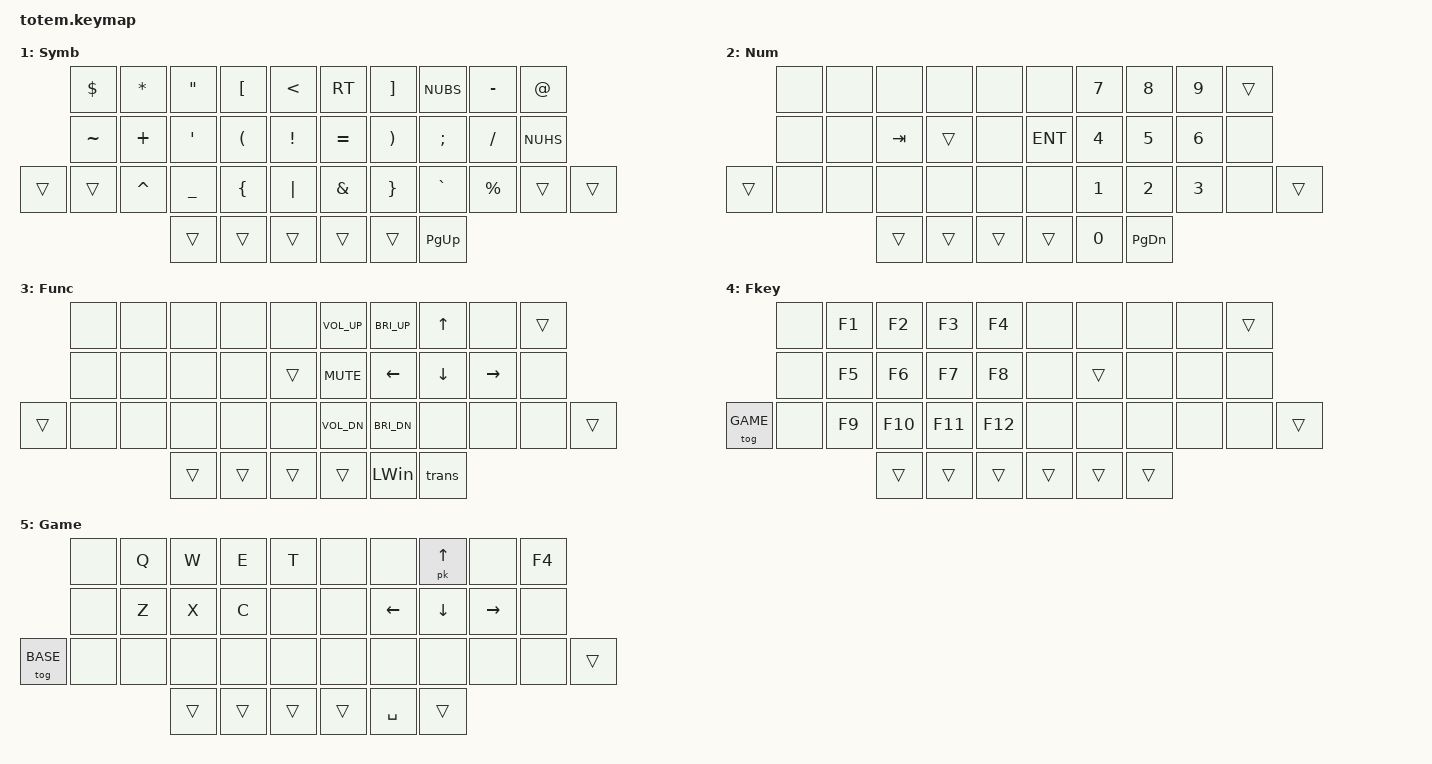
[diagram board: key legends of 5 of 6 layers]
//
//                                                        ▀▀▀▀▀     ▀▀▀▀▀          ▀▀█▀▀
//                                                        ▄▀▀▀▄  ▄  ▄▀▀▀▄  ▄  ▄▀▀▀▄  █  ▄▀▀▀▄
//                                                        █   █  █  █   █  █  █   █  █  █   █
//                                                         ▀▀▀   █   ▀▀▀   █   ▀▀▀   ▀   ▀▀▀
//                                                               █      ▄▄▄█▄▄▄    █   █  
//                                                               ▀      █  █  █     █▄█
//                                                             ▀▀▀▀▀    █  █  █      ▀
//                                                                      ▀  ▀  ▀
//
// ▄▄▄▄▄▄▄▄▄▄▄▄▄▄▄▄▄▄▄▄▄▄▄▄▄▄▄▄▄▄▄▄▄▄▄▄▄▄▄▄▄▄▄▄▄▄▄▄▄▄▄▄▄▄▄▄▄▄▄▄▄▄▄▄▄▄▄▄▄▄▄▄▄▄▄▄▄▄▄▄▄▄▄▄▄▄▄▄▄▄▄▄▄▄▄▄▄▄▄▄▄▄▄▄▄▄▄▄▄▄▄▄▄▄▄▄▄▄▄▄▄▄▄▄▄▄▄▄▄▄▄▄▄▄▄▄▄▄▄▄▄▄▄▄▄▄▄▄▄
       

#include <behaviors.dtsi>
#include <dt-bindings/zmk/keys.h>
#include <dt-bindings/zmk/bt.h>
#include <dt-bindings/zmk/outputs.h>

#define BASE 0
#define SYMB 1
#define NUM  2
#define FUNC 3
#define FKEY 4
#define GAME 5

&mt {
  flavor = "tap-preferred";
};

/ {
    combos {
            compatible = "zmk,combos";
            combo_esc {
                timeout-ms = <50>;
                key-positions = <0 1>;
                bindings = <&kp ESC>;
            };
                                                                                                           
    };

        keymap {
                compatible = "zmk,keymap";
// ▄▄▄▄▄▄▄▄▄▄▄▄▄▄▄▄▄▄▄▄▄▄▄▄▄▄▄▄▄▄▄▄▄▄▄▄▄▄▄▄▄▄▄▄▄▄▄▄▄▄▄▄▄▄▄▄▄▄▄▄▄▄▄▄▄▄▄▄▄▄▄▄▄▄▄▄▄▄▄▄▄▄▄▄▄▄▄▄▄▄▄▄▄▄▄▄▄▄▄▄▄▄▄▄▄▄▄▄▄▄▄▄▄▄▄▄▄▄▄▄▄▄▄▄▄▄▄▄▄▄▄▄▄▄▄▄▄▄▄▄▄▄▄▄▄▄▄▄▄

                base_layer {
// ┏━━━━━━━━━━━━━━━━━━━━━━━━━━━━━━━━━━━━━━━┓
display-name = "Base";           //layer 0 ┃
// ┗━━━━━━━━━━━━━━━━━━━━━━━━━━━━━━━━━━━━━━━┛
//             ┏━━━━━━━━━━━┳━━━━━━━━━━━┳━━━━━━━━━━━┳━━━━━━━━━━━┳━━━━━━━━━━━┓   ┏━━━━━━━━━━━┳━━━━━━━━━━━┳━━━━━━━━━━━┳━━━━━━━━━━━┳━━━━━━━━━━━┓
//             ┃     Q     ┃     W     ┃     F     ┃     P     ┃     G     ┃   ┃     J     ┃     L     ┃     U     ┃     Y     ┃     ;     ┃
//             ┣━━━━━━━━━━━╋━━━━━━━━━━━╋━━━━━━━━━━━╋━━━━━━━━━━━╋━━━━━━━━━━━┫   ┣━━━━━━━━━━━╋━━━━━━━━━━━╋━━━━━━━━━━━╋━━━━━━━━━━━╋━━━━━━━━━━━┫
//             ┃     A     ┃     R     ┃     S     ┃     T     ┃     D     ┃   ┃     H     ┃     N     ┃     E     ┃     I     ┃     O     ┃
// ┏━━━━━━━━━━━╋━━━━━━━━━━━╋━━━━━━━━━━━╋━━━━━━━━━━━╋━━━━━━━━━━━╋━━━━━━━━━━━┫   ┣━━━━━━━━━━━╋━━━━━━━━━━━╋━━━━━━━━━━━╋━━━━━━━━━━━╋━━━━━━━━━━━╋━━━━━━━━━━━┓
// ┃   CAPS    ┃     Z     ┃     X     ┃     C     ┃     V     ┃     B     ┃   ┃     K     ┃     M     ┃     ,     ┃     .     ┃     /     ┃ PRNT SCRN ┃
// ┗━━━━━━━━━━━┻━━━━━━━━━━━┻━━━━━━━━━━━╋━━━━━━━━━━━╋━━━━━━━━━━━╋━━━━━━━━━━━┫   ┣━━━━━━━━━━━╋━━━━━━━━━━━╋━━━━━━━━━━━╋━━━━━━━━━━━┻━━━━━━━━━━━┻━━━━━━━━━━━┛
//                                     ┃    ALT    ┃   SHIFT   ┃   Symb    ┃   ┃    CTR    ┃    SPC    ┃    END    ┃
//                                     ┗━━━━━━━━━━━┻━━━━━━━━━━━┻━━━━━━━━━━━┛   ┗━━━━━━━━━━━┻━━━━━━━━━━━┻━━━━━━━━━━━┛
 bindings = <
// ╷           ╷           ╷           ╷           ╷           ╷           ╷   ╷           ╷           ╷           ╷           ╷           ╷           ╷

                &kp Q       &kp W       &kp F       &kp P       &kp G           &kp J       &kp L       &kp U       &kp Y       &kp DEL
                &kp A       &kp R       &kp S       &lt NUM T   &lt FUNC D      &kp H       &lt FKEY N  &kp E       &kp I       &kp O
    &kp CAPS    &kp Z       &kp X       &kp C       &kp V       &kp B           &kp K       &kp M       &kp LS(COLON) COMMA   &kp LD(QMARK) DOT     &kp FSLH    &lt FKEY PSCRN
                                        &kp LALT    &kp LSHIFT  &mo SYMB           &kp CTR   &kp LS(BSPC) SPC   &kp LS(HOME) END
                        >;
                };

// ▄▄▄▄▄▄▄▄▄▄▄▄▄▄▄▄▄▄▄▄▄▄▄▄▄▄▄▄▄▄▄▄▄▄▄▄▄▄▄▄▄▄▄▄▄▄▄▄▄▄▄▄▄▄▄▄▄▄▄▄▄▄▄▄▄▄▄▄▄▄▄▄▄▄▄▄▄▄▄▄▄▄▄▄▄▄▄▄▄▄▄▄▄▄▄▄▄▄▄▄▄▄▄▄▄▄▄▄▄▄▄▄▄▄▄▄▄▄▄▄▄▄▄▄▄▄▄▄▄▄▄▄▄▄▄▄▄▄▄▄▄▄▄▄▄▄▄▄▄


                symb_layer {
// ┏━━━━━━━━━━━━━━━━━━━━━━━━━━━━━━━━━━━━━━━┓
display-name = "Symb";           //layer 1 ┃
// ┗━━━━━━━━━━━━━━━━━━━━━━━━━━━━━━━━━━━━━━━┛
//             ┏━━━━━━━━━━━┳━━━━━━━━━━━┳━━━━━━━━━━━┳━━━━━━━━━━━┳━━━━━━━━━━━┓   ┏━━━━━━━━━━━┳━━━━━━━━━━━┳━━━━━━━━━━━┳━━━━━━━━━━━┳━━━━━━━━━━━┓
//             ┃     $     ┃     *     ┃     "     ┃     [     ┃     <     ┃   ┃     >     ┃     ]     ┃     \     ┃     -     ┃     @     ┃
//             ┣━━━━━━━━━━━╋━━━━━━━━━━━╋━━━━━━━━━━━╋━━━━━━━━━━━╋━━━━━━━━━━━┫   ┣━━━━━━━━━━━╋━━━━━━━━━━━╋━━━━━━━━━━━╋━━━━━━━━━━━╋━━━━━━━━━━━┫
//             ┃     ~     ┃     +     ┃     '     ┃     (     ┃     !     ┃   ┃     =     ┃     )     ┃     ;     ┃     /     ┃     #     ┃
// ┏━━━━━━━━━━━╋━━━━━━━━━━━╋━━━━━━━━━━━╋━━━━━━━━━━━╋━━━━━━━━━━━╋━━━━━━━━━━━┫   ┣━━━━━━━━━━━╋━━━━━━━━━━━╋━━━━━━━━━━━╋━━━━━━━━━━━╋━━━━━━━━━━━╋━━━━━━━━━━━┓
// ┃           ┃           ┃     ^     ┃     _     ┃     {     ┃     |     ┃   ┃     &     ┃     }     ┃     `     ┃     %     ┃           ┃           ┃
// ┗━━━━━━━━━━━┻━━━━━━━━━━━┻━━━━━━━━━━━╋━━━━━━━━━━━╋━━━━━━━━━━━╋━━━━━━━━━━━┫   ┣━━━━━━━━━━━╋━━━━━━━━━━━╋━━━━━━━━━━━╋━━━━━━━━━━━┻━━━━━━━━━━━┻━━━━━━━━━━━┛
//                                     ┃           ┃           ┃   Symb    ┃   ┃           ┃           ┃   PG_UP   ┃
//                                     ┗━━━━━━━━━━━┻━━━━━━━━━━━┻━━━━━━━━━━━┛   ┗━━━━━━━━━━━┻━━━━━━━━━━━┻━━━━━━━━━━━┛
 bindings = <
// ╷           ╷           ╷           ╷           ╷           ╷           ╷   ╷           ╷           ╷           ╷           ╷           ╷           ╷

                &kp DLLR    &kp STAR    &kp DQT     &kp LBKT    &kp LT          &kp RT      &kp RBKT    &kp NUBS    &kp MINUS   &kp AT
                &kp TILDE   &kp PLUS    &kp SQT     &kp LPAR    &kp EXCL        &kp EQUAL   &kp RPAR    &kp SEMI    &kp FSLH    &kp NUHS
    &trans      &trans      &kp CARET   &kp UNDER   &kp LBRC    &kp PIPE        &kp AMPS    &kp RBRC    &kp GRAVE   &kp PRCNT   &trans    &trans      
                                        &trans      &trans      &trans          &trans      &trans      &kp PG_UP
                        >;
                };

// ▄▄▄▄▄▄▄▄▄▄▄▄▄▄▄▄▄▄▄▄▄▄▄▄▄▄▄▄▄▄▄▄▄▄▄▄▄▄▄▄▄▄▄▄▄▄▄▄▄▄▄▄▄▄▄▄▄▄▄▄▄▄▄▄▄▄▄▄▄▄▄▄▄▄▄▄▄▄▄▄▄▄▄▄▄▄▄▄▄▄▄▄▄▄▄▄▄▄▄▄▄▄▄▄▄▄▄▄▄▄▄▄▄▄▄▄▄▄▄▄▄▄▄▄▄▄▄▄▄▄▄▄▄▄▄▄▄▄▄▄▄▄▄▄▄▄▄▄▄


                num_layer {
// ┏━━━━━━━━━━━━━━━━━━━━━━━━━━━━━━━━━━━━━━━┓
display-name = "Num";            //layer 2 ┃
// ┗━━━━━━━━━━━━━━━━━━━━━━━━━━━━━━━━━━━━━━━┛
//             ┏━━━━━━━━━━━┳━━━━━━━━━━━┳━━━━━━━━━━━┳━━━━━━━━━━━┳━━━━━━━━━━━┓   ┏━━━━━━━━━━━┳━━━━━━━━━━━┳━━━━━━━━━━━┳━━━━━━━━━━━┳━━━━━━━━━━━┓
//             ┃           ┃           ┃           ┃           ┃           ┃   ┃           ┃     7     ┃     8     ┃     9     ┃           ┃
//             ┣━━━━━━━━━━━╋━━━━━━━━━━━╋━━━━━━━━━━━╋━━━━━━━━━━━╋━━━━━━━━━━━┫   ┣━━━━━━━━━━━╋━━━━━━━━━━━╋━━━━━━━━━━━╋━━━━━━━━━━━╋━━━━━━━━━━━┫
//             ┃           ┃           ┃    TAB    ┃     T     ┃           ┃   ┃   ENTER   ┃     4     ┃     5     ┃     6     ┃           ┃
// ┏━━━━━━━━━━━╋━━━━━━━━━━━╋━━━━━━━━━━━╋━━━━━━━━━━━╋━━━━━━━━━━━╋━━━━━━━━━━━┫   ┣━━━━━━━━━━━╋━━━━━━━━━━━╋━━━━━━━━━━━╋━━━━━━━━━━━╋━━━━━━━━━━━╋━━━━━━━━━━━┓
// ┃           ┃           ┃           ┃           ┃           ┃           ┃   ┃           ┃     1     ┃     2     ┃     3     ┃           ┃           ┃
// ┗━━━━━━━━━━━┻━━━━━━━━━━━┻━━━━━━━━━━━╋━━━━━━━━━━━╋━━━━━━━━━━━╋━━━━━━━━━━━┫   ┣━━━━━━━━━━━╋━━━━━━━━━━━╋━━━━━━━━━━━╋━━━━━━━━━━━┻━━━━━━━━━━━┻━━━━━━━━━━━┛
//                                     ┃           ┃           ┃           ┃   ┃           ┃     0     ┃   PG_DN   ┃
//                                     ┗━━━━━━━━━━━┻━━━━━━━━━━━┻━━━━━━━━━━━┛   ┗━━━━━━━━━━━┻━━━━━━━━━━━┻━━━━━━━━━━━┛
 bindings = <
// ╷           ╷           ╷           ╷           ╷           ╷           ╷   ╷           ╷           ╷           ╷           ╷           ╷           ╷

                &none       &none       &none       &none       &none           &none       &kp N7      &kp N8     &kp N9       &trans       
                &none       &none       &kp TAB     &trans      &none           &kp ENT     &kp N4      &kp N5     &kp N6       &none 
    &trans      &none       &none       &none       &none       &none           &none       &kp N1      &kp N2     &kp N3       &none   &trans         
                                        &trans      &trans      &trans          &trans      &kp N0      &kp PG_DN
                        >;
                };

// ▄▄▄▄▄▄▄▄▄▄▄▄▄▄▄▄▄▄▄▄▄▄▄▄▄▄▄▄▄▄▄▄▄▄▄▄▄▄▄▄▄▄▄▄▄▄▄▄▄▄▄▄▄▄▄▄▄▄▄▄▄▄▄▄▄▄▄▄▄▄▄▄▄▄▄▄▄▄▄▄▄▄▄▄▄▄▄▄▄▄▄▄▄▄▄▄▄▄▄▄▄▄▄▄▄▄▄▄▄▄▄▄▄▄▄▄▄▄▄▄▄▄▄▄▄▄▄▄▄▄▄▄▄▄▄▄▄▄▄▄▄▄▄▄▄▄▄▄▄


                func_layer {
// ┏━━━━━━━━━━━━━━━━━━━━━━━━━━━━━━━━━━━━━━━┓
display-name = "Func";           //layer 3 ┃
// ┗━━━━━━━━━━━━━━━━━━━━━━━━━━━━━━━━━━━━━━━┛
//             ┏━━━━━━━━━━━┳━━━━━━━━━━━┳━━━━━━━━━━━┳━━━━━━━━━━━┳━━━━━━━━━━━┓   ┏━━━━━━━━━━━┳━━━━━━━━━━━┳━━━━━━━━━━━┳━━━━━━━━━━━┳━━━━━━━━━━━┓
//             ┃           ┃           ┃           ┃           ┃           ┃   ┃ SOUND UP  ┃ BRIGHT UP ┃    UP     ┃           ┃           ┃
//             ┣━━━━━━━━━━━╋━━━━━━━━━━━╋━━━━━━━━━━━╋━━━━━━━━━━━╋━━━━━━━━━━━┫   ┣━━━━━━━━━━━╋━━━━━━━━━━━╋━━━━━━━━━━━╋━━━━━━━━━━━╋━━━━━━━━━━━┫
//             ┃           ┃           ┃           ┃           ┃     D     ┃   ┃ SOUND OFF ┃   LEFT    ┃   DOWN    ┃   RIGHT   ┃           ┃
// ┏━━━━━━━━━━━╋━━━━━━━━━━━╋━━━━━━━━━━━╋━━━━━━━━━━━╋━━━━━━━━━━━╋━━━━━━━━━━━┫   ┣━━━━━━━━━━━╋━━━━━━━━━━━╋━━━━━━━━━━━╋━━━━━━━━━━━╋━━━━━━━━━━━╋━━━━━━━━━━━┓
// ┃           ┃           ┃           ┃           ┃           ┃           ┃   ┃ SOUND DWN ┃ BRIGHT DN ┃           ┃           ┃           ┃           ┃
// ┗━━━━━━━━━━━┻━━━━━━━━━━━┻━━━━━━━━━━━╋━━━━━━━━━━━╋━━━━━━━━━━━╋━━━━━━━━━━━┫   ┣━━━━━━━━━━━╋━━━━━━━━━━━╋━━━━━━━━━━━╋━━━━━━━━━━━┻━━━━━━━━━━━┻━━━━━━━━━━━┛
//                                     ┃           ┃           ┃           ┃   ┃           ┃    WIN    ┃           ┃
//                                     ┗━━━━━━━━━━━┻━━━━━━━━━━━┻━━━━━━━━━━━┛   ┗━━━━━━━━━━━┻━━━━━━━━━━━┻━━━━━━━━━━━┛
 bindings = <
/ ╷           ╷           ╷           ╷           ╷           ╷           ╷   ╷           ╷           ╷           ╷           ╷           ╷           ╷

                &none       &none       &none       &none       &none           &kp C_VOL_UP   &kp C_BRI_UP   &kp UP     &none       &trans       
                &none       &none       &none       &none       &trans           &kp C_MUTE     &kp LEFT       &kp DOWN   &kp RIGHT   &none 
    &trans      &none       &none       &none       &none       &none           &kp C_VOL_DN   &kp C_BRI_DN   &none      &none       &none   &trans         
                                        &trans      &trans      &trans          &trans         &kp LWIN       &kp trans
                        >;
                };

// ▄▄▄▄▄▄▄▄▄▄▄▄▄▄▄▄▄▄▄▄▄▄▄▄▄▄▄▄▄▄▄▄▄▄▄▄▄▄▄▄▄▄▄▄▄▄▄▄▄▄▄▄▄▄▄▄▄▄▄▄▄▄▄▄▄▄▄▄▄▄▄▄▄▄▄▄▄▄▄▄▄▄▄▄▄▄▄▄▄▄▄▄▄▄▄▄▄▄▄▄▄▄▄▄▄▄▄▄▄▄▄▄▄▄▄▄▄▄▄▄▄▄▄▄▄▄▄▄▄▄▄▄▄▄▄▄▄▄▄▄▄▄▄▄▄▄▄▄▄


                fkey_layer {
// ┏━━━━━━━━━━━━━━━━━━━━━━━━━━━━━━━━━━━━━━━┓
display-name = "Fkey";           //layer 4 ┃
// ┗━━━━━━━━━━━━━━━━━━━━━━━━━━━━━━━━━━━━━━━┛
//             ┏━━━━━━━━━━━┳━━━━━━━━━━━┳━━━━━━━━━━━┳━━━━━━━━━━━┳━━━━━━━━━━━┓   ┏━━━━━━━━━━━┳━━━━━━━━━━━┳━━━━━━━━━━━┳━━━━━━━━━━━┳━━━━━━━━━━━┓
//             ┃           ┃    F1     ┃    F2     ┃    F3     ┃    F4     ┃   ┃           ┃           ┃           ┃           ┃           ┃
//             ┣━━━━━━━━━━━╋━━━━━━━━━━━╋━━━━━━━━━━━╋━━━━━━━━━━━╋━━━━━━━━━━━┫   ┣━━━━━━━━━━━╋━━━━━━━━━━━╋━━━━━━━━━━━╋━━━━━━━━━━━╋━━━━━━━━━━━┫
//             ┃           ┃    F5     ┃    F6     ┃    F7     ┃    F8     ┃   ┃           ┃     N     ┃           ┃           ┃           ┃
// ┏━━━━━━━━━━━╋━━━━━━━━━━━╋━━━━━━━━━━━╋━━━━━━━━━━━╋━━━━━━━━━━━╋━━━━━━━━━━━┫   ┣━━━━━━━━━━━╋━━━━━━━━━━━╋━━━━━━━━━━━╋━━━━━━━━━━━╋━━━━━━━━━━━╋━━━━━━━━━━━┓
// ┃   Game    ┃           ┃    F9     ┃    F10    ┃    F11    ┃    F12    ┃   ┃           ┃           ┃           ┃           ┃           ┃           ┃
// ┗━━━━━━━━━━━┻━━━━━━━━━━━┻━━━━━━━━━━━╋━━━━━━━━━━━╋━━━━━━━━━━━╋━━━━━━━━━━━┫   ┣━━━━━━━━━━━╋━━━━━━━━━━━╋━━━━━━━━━━━╋━━━━━━━━━━━┻━━━━━━━━━━━┻━━━━━━━━━━━┛
//                                     ┃           ┃           ┃           ┃   ┃    CTR    ┃           ┃           ┃
//                                     ┗━━━━━━━━━━━┻━━━━━━━━━━━┻━━━━━━━━━━━┛   ┗━━━━━━━━━━━┻━━━━━━━━━━━┻━━━━━━━━━━━┛
 bindings = <
// ╷           ╷           ╷           ╷           ╷           ╷           ╷   ╷           ╷           ╷           ╷           ╷           ╷           ╷

                &none       &kp F1      &kp F2      &kp F3      &kp F4          &none       &none       &none       &none       &trans       
                &none       &kp F5      &kp F6      &kp F7      &kp F8          &none       &trans      &none       &none       &none 
    &tog GAME   &none       &kp F9      &kp F10     &kp F11     &kp F12         &none       &none       &none       &none       &none       &trans         
                                        &trans      &trans      &trans          &trans      &trans      &trans
                        >;
                };

// ▄▄▄▄▄▄▄▄▄▄▄▄▄▄▄▄▄▄▄▄▄▄▄▄▄▄▄▄▄▄▄▄▄▄▄▄▄▄▄▄▄▄▄▄▄▄▄▄▄▄▄▄▄▄▄▄▄▄▄▄▄▄▄▄▄▄▄▄▄▄▄▄▄▄▄▄▄▄▄▄▄▄▄▄▄▄▄▄▄▄▄▄▄▄▄▄▄▄▄▄▄▄▄▄▄▄▄▄▄▄▄▄▄▄▄▄▄▄▄▄▄▄▄▄▄▄▄▄▄▄▄▄▄▄▄▄▄▄▄▄▄▄▄▄▄▄▄▄▄


                game_layer {
// ┏━━━━━━━━━━━━━━━━━━━━━━━━━━━━━━━━━━━━━━━┓
display-name = "Game";           //layer 5 ┃
// ┗━━━━━━━━━━━━━━━━━━━━━━━━━━━━━━━━━━━━━━━┛
//             ┏━━━━━━━━━━━┳━━━━━━━━━━━┳━━━━━━━━━━━┳━━━━━━━━━━━┳━━━━━━━━━━━┓   ┏━━━━━━━━━━━┳━━━━━━━━━━━┳━━━━━━━━━━━┳━━━━━━━━━━━┳━━━━━━━━━━━┓
//             ┃    ESC    ┃     Q     ┃     W     ┃     E     ┃     T     ┃   ┃           ┃           ┃    UP     ┃           ┃    F4     ┃
//             ┣━━━━━━━━━━━╋━━━━━━━━━━━╋━━━━━━━━━━━╋━━━━━━━━━━━╋━━━━━━━━━━━┫   ┣━━━━━━━━━━━╋━━━━━━━━━━━╋━━━━━━━━━━━╋━━━━━━━━━━━╋━━━━━━━━━━━┫
//             ┃           ┃     Z     ┃     X     ┃     C     ┃           ┃   ┃           ┃   LEFT    ┃   DOWN    ┃   RIGHT   ┃           ┃
// ┏━━━━━━━━━━━╋━━━━━━━━━━━╋━━━━━━━━━━━╋━━━━━━━━━━━╋━━━━━━━━━━━╋━━━━━━━━━━━┫   ┣━━━━━━━━━━━╋━━━━━━━━━━━╋━━━━━━━━━━━╋━━━━━━━━━━━╋━━━━━━━━━━━╋━━━━━━━━━━━┓
// ┃   Game    ┃           ┃           ┃           ┃           ┃           ┃   ┃           ┃           ┃           ┃           ┃           ┃           ┃
// ┗━━━━━━━━━━━┻━━━━━━━━━━━┻━━━━━━━━━━━╋━━━━━━━━━━━╋━━━━━━━━━━━╋━━━━━━━━━━━┫   ┣━━━━━━━━━━━╋━━━━━━━━━━━╋━━━━━━━━━━━╋━━━━━━━━━━━┻━━━━━━━━━━━┻━━━━━━━━━━━┛
//                                     ┃           ┃           ┃           ┃   ┃           ┃    SPC    ┃           ┃
//                                     ┗━━━━━━━━━━━┻━━━━━━━━━━━┻━━━━━━━━━━━┛   ┗━━━━━━━━━━━┻━━━━━━━━━━━┻━━━━━━━━━━━┛
 bindings = <
// ╷           ╷           ╷           ╷           ╷           ╷           ╷   ╷           ╷           ╷           ╷           ╷           ╷           ╷

                &none       &kp Q       &kp W       &kp E       &kp T           &none       &none       &pk UP      &none       &kp F4       
                &none       &kp Z       &kp X       &kp C       &none           &none       &kp LEFT    &kp DOWN    &kp RIGHT   &none 
    &tog BASE   &none       &none       &none       &none       &none           &none       &none       &none       &none       &none       &trans         
                                        &trans      &trans      &trans          &trans      &kp SPACE   &trans
                        >;
                };










        };
};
